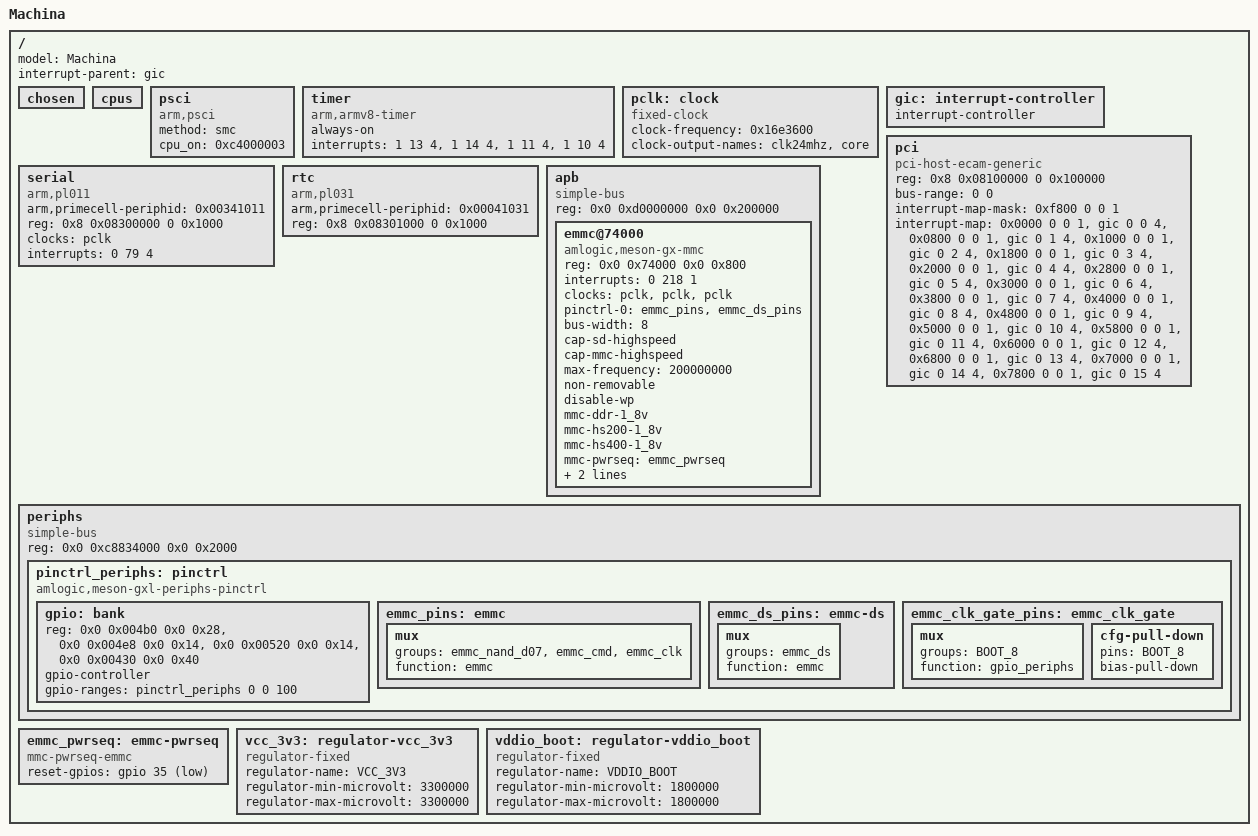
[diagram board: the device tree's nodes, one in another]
// Copyright 2017 The Fuchsia Authors. All rights reserved.
// Use of this source code is governed by a BSD-style license that can be
// found in the LICENSE file.

// See: https://elinux.org/Device_Tree_Usage
/dts-v1/;

/ {
  model = "Machina";
  interrupt-parent = <&gic>;
  #address-cells = <2>;
  #size-cells = <2>;

  chosen {
    // Will be populated at run-time.
  };

  cpus {
    #address-cells = <1>;
    #size-cells = <0>;
    // CPU list will be populated at run-time.
  };

  psci {
    compatible = "arm,psci";
    method = "smc";
    cpu_on = <0xc4000003>;
  };

  timer {
    compatible = "arm,armv8-timer";
    always-on;
    interrupts = <1 13 4>, // PHYS-SECURE-PPI     29 HIGH/CPU-0
                 <1 14 4>, // PHYS-NON-SECURE-PPI 30 HIGH/CPU-0
                 <1 11 4>, // VIRT-PPI            27 HIGH/CPU-0
                 <1 10 4>; // HYP-PPI             26 HIGH/CPU-0
  };

  pclk: clock {
    compatible = "fixed-clock";
    clock-frequency = <0x16e3600>;
    clock-output-names = "clk24mhz", "core";
    #clock-cells = <0>;
  };

  gic: interrupt-controller {
    interrupt-controller;
    #address-cells = <0>;
    #interrupt-cells = <3>;
    // Interrupt controller is populated at run-time.
  };

  pci {
    device_type = "pci";
    compatible = "pci-host-ecam-generic";
    reg = <0x8 0x08100000 0 0x100000>;
    bus-range = <0 0>;
    ranges = <0x2000000 0x8 0x08201000 0x8 0x08201000 0 0xff000>;
    interrupt-map-mask = <0xf800 0 0 1>;
    interrupt-map = <0x0000 0 0 1 &gic 0 0 4>,  // HIGH MID LOW WIRE GIC SPI 32 HIGH/CPU-0
                    <0x0800 0 0 1 &gic 0 1 4>,  // HIGH MID LOW WIRE GIC SPI 33 HIGH/CPU-0
                    <0x1000 0 0 1 &gic 0 2 4>,  // HIGH MID LOW WIRE GIC SPI 34 HIGH/CPU-0
                    <0x1800 0 0 1 &gic 0 3 4>,  // HIGH MID LOW WIRE GIC SPI 35 HIGH/CPU-0
                    <0x2000 0 0 1 &gic 0 4 4>,  // HIGH MID LOW WIRE GIC SPI 36 HIGH/CPU-0
                    <0x2800 0 0 1 &gic 0 5 4>,  // HIGH MID LOW WIRE GIC SPI 37 HIGH/CPU-0
                    <0x3000 0 0 1 &gic 0 6 4>,  // HIGH MID LOW WIRE GIC SPI 38 HIGH/CPU-0
                    <0x3800 0 0 1 &gic 0 7 4>,  // HIGH MID LOW WIRE GIC SPI 39 HIGH/CPU-0
                    <0x4000 0 0 1 &gic 0 8 4>,  // HIGH MID LOW WIRE GIC SPI 40 HIGH/CPU-0
                    <0x4800 0 0 1 &gic 0 9 4>,  // HIGH MID LOW WIRE GIC SPI 41 HIGH/CPU-0
                    <0x5000 0 0 1 &gic 0 10 4>, // HIGH MID LOW WIRE GIC SPI 42 HIGH/CPU-0
                    <0x5800 0 0 1 &gic 0 11 4>, // HIGH MID LOW WIRE GIC SPI 43 HIGH/CPU-0
                    <0x6000 0 0 1 &gic 0 12 4>, // HIGH MID LOW WIRE GIC SPI 44 HIGH/CPU-0
                    <0x6800 0 0 1 &gic 0 13 4>, // HIGH MID LOW WIRE GIC SPI 45 HIGH/CPU-0
                    <0x7000 0 0 1 &gic 0 14 4>, // HIGH MID LOW WIRE GIC SPI 46 HIGH/CPU-0
                    <0x7800 0 0 1 &gic 0 15 4>; // HIGH MID LOW WIRE GIC SPI 47 HIGH/CPU-0
    #address-cells = <3>;
    #size-cells = <2>;
    #interrupt-cells = <1>;
  };

  serial {
    compatible = "arm,pl011", "arm,primecell";
    arm,primecell-periphid = <0x00341011>;
    reg = <0x8 0x08300000 0 0x1000>;
    clock-names = "apb_pclk";
    clocks = <&pclk>;
    interrupts = <0 79 4>; // SPI 111 HIGH/CPU-0
  };

  rtc {
    compatible = "arm,pl031", "arm,primecell";
    arm,primecell-periphid = <0x00041031>;
    reg = <0x8 0x08301000 0 0x1000>;
  };

  apb {
    compatible = "simple-bus";
    reg = <0x0 0xd0000000 0x0 0x200000>;
    #address-cells = <2>;
    #size-cells = <2>;
    ranges = <0x0 0x0 0x0 0xd0000000 0x0 0x200000>;

    emmc@74000 {
      compatible = "amlogic,meson-gx-mmc", "amlogic,meson-gxbb-mmc";
      reg = <0x0 0x74000 0x0 0x800>;
      interrupts = <0 218 1>;
      status = "okay";

      clocks = <&pclk>, <&pclk>, <&pclk>;
	    clock-names = "core", "clkin0", "clkin1";

      pinctrl-0 = <&emmc_pins>, <&emmc_ds_pins>;
      pinctrl-names = "default";

      bus-width = <8>;
      cap-sd-highspeed;
      cap-mmc-highspeed;
      max-frequency = <200000000>;
      non-removable;
      disable-wp;
      mmc-ddr-1_8v;
      mmc-hs200-1_8v;
      mmc-hs400-1_8v;

      mmc-pwrseq = <&emmc_pwrseq>;
      vmmc-supply = <&vcc_3v3>;
      vqmmc-supply = <&vddio_boot>;
    };
  };

  periphs {
    compatible = "simple-bus";
    reg = <0x0 0xc8834000 0x0 0x2000>;
    #address-cells = <2>;
    #size-cells = <2>;
    ranges = <0x0 0x0 0x0 0xc8834000 0x0 0x2000>;

    pinctrl_periphs: pinctrl {
      compatible = "amlogic,meson-gxl-periphs-pinctrl";
      #address-cells = <2>;
      #size-cells = <2>;
      ranges;

      gpio: bank {
        reg = <0x0 0x004b0 0x0 0x28>,
              <0x0 0x004e8 0x0 0x14>,
              <0x0 0x00520 0x0 0x14>,
              <0x0 0x00430 0x0 0x40>;
        reg-names = "mux", "pull", "pull-enable", "gpio";
        gpio-controller;
        #gpio-cells = <2>;
        gpio-ranges = <&pinctrl_periphs 0 0 100>;
      };

      emmc_pins: emmc {
        mux {
          groups = "emmc_nand_d07", "emmc_cmd", "emmc_clk";
          function = "emmc";
        };
      };

      emmc_ds_pins: emmc-ds {
        mux {
          groups = "emmc_ds";
          function = "emmc";
        };
      };

      emmc_clk_gate_pins: emmc_clk_gate {
        mux {
          groups = "BOOT_8";
          function = "gpio_periphs";
        };
        cfg-pull-down {
          pins = "BOOT_8";
          bias-pull-down;
        };
      };
    };
  };

  emmc_pwrseq: emmc-pwrseq {
		compatible = "mmc-pwrseq-emmc";
		reset-gpios = <&gpio 35 1>;
	};

	vcc_3v3: regulator-vcc_3v3 {
		compatible = "regulator-fixed";
		regulator-name = "VCC_3V3";
		regulator-min-microvolt = <3300000>;
		regulator-max-microvolt = <3300000>;
	};

	vddio_boot: regulator-vddio_boot {
		compatible = "regulator-fixed";
		regulator-name = "VDDIO_BOOT";
		regulator-min-microvolt = <1800000>;
		regulator-max-microvolt = <1800000>;
	};
};
